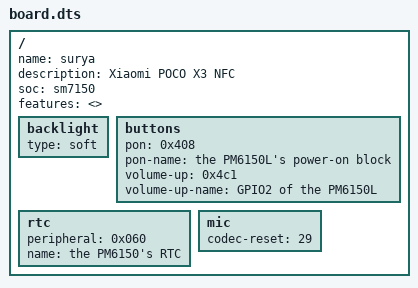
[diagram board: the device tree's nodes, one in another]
/dts-v1/;

// Xiaomi POCO X3 NFC. Started by tools/boards.py new from surya.dts.
// Every value here is to be checked against the device before it is relied on (Documentation/porting.md).
/ {
	name = "surya";                         // what the loader puts in /chosen/darwin-board
	description = "Xiaomi POCO X3 NFC";
	soc = "sm7150";

	// Nothing yet: a feature is listed once its driver has been seen to work on this board
	// (Documentation/porting.md goes through them in the order to try).
	features = <>;

	// The panel: qcom,mdss_dsi_nt36672c_tianma_fhd_video ("nt36672c tianma fhd video mode dsi panel")
	backlight {
		type = "soft";
	};

	// The keys on the PMICs, for the feature "buttons-pmic": SPMI slave << 8 | the high byte of the
	// peripheral's registers.
	buttons {
		pon = <0x408>;
		pon-name = "the PM6150L's power-on block";
		volume-up = <0x4c1>;
		volume-up-name = "GPIO2 of the PM6150L";
	};

	// The PMIC's real-time clock, read once at boot (rtc=0 leaves it alone): SPMI slave << 8 | the high byte
	// of its RTC_RW block's registers.
	rtc {
		peripheral = <0x060>;
		name = "the PM6150's RTC";
	};

	// The audio DSP, for the feature "adsp": its reserved memory is from the tree; the directory with
	// this phone's adsp.mdt and its parts is yours to name (arch/arm64/boot/dts/_template/board.dts).
	// adsp {
		// firmware = "fw-audio-surya";
		// memory = <0x95700000>;
		// memory-size = <0x01e00000>;
	// };

	// The microphones' codec, for the feature "mic-wcd938x": its reset pin is from the tree.
	mic {
		codec-reset = <29>;
	};
};
